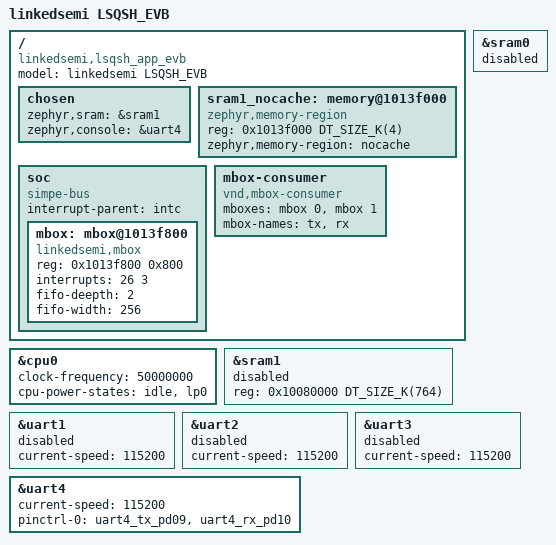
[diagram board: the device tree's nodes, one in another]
/*
 * Copyright (c) 2021, Teslabs Engineering S.L.
 * SPDX-License-Identifier: Apache-2.0
 */

// #include <gigadevice/gd32vf103Xb.dtsi>
// #include "gd32vf103v_eval-pinctrl.dtsi"
/dts-v1/;
#include <riscv/linkedsemi/lsqsh.dtsi>
#include "lsqsh_evb-pinctrl.dtsi"
#include <zephyr/dt-bindings/pinctrl/lsqsh-pinctrl.h>

#define BTN_GPIO_FLAGS (GPIO_ACTIVE_HIGH | GPIO_PULL_UP)

/ {
    model = "linkedsemi LSQSH_EVB";
    compatible = "linkedsemi,lsqsh_app_evb";

    chosen {
        zephyr,sram = &sram1;
        zephyr,console = &uart4;
    };

    sram1_nocache: memory@1013f000{
        compatible = "zephyr,memory-region", "mmio-sram";
        reg = <0x1013f000 DT_SIZE_K(4)>;
        device_type = "memory";
        zephyr,memory-region = "nocache";
    };

    soc {
        compatible = "simpe-bus";
        #address-cells = <1>;
        #size-cells = <1>;
        interrupt-parent = <&intc>;

        mbox: mbox@1013f800 {
            compatible = "linkedsemi,mbox";
            reg = <0x1013f800 0x800>;
            interrupts = <26 3>;
            fifo-deepth = <2>;
            fifo-width = <256>;
            #mbox-cells = <1>;
        };
    };

    mbox-consumer {
        compatible = "vnd,mbox-consumer";
        mboxes = <&mbox 0>, <&mbox 1>;
        mbox-names = "tx", "rx";
    };
};

&cpu0 {
    clock-frequency = <50000000>;
    cpu-power-states = <&idle &lp0>;
};

&sram0 {
    status = "disabled";
};

&sram1 {
    reg = <0x10080000 DT_SIZE_K(764)>;
    status = "disabled";
};

&uart1 {
    status = "disabled";
    current-speed = <115200>;
};

&uart2 {
    status = "disabled";
    current-speed = <115200>;
};

&uart3 {
    status = "disabled";
    current-speed = <115200>;
};

&uart4 {
    status = "okay";
    current-speed = <115200>;
    pinctrl-0 = <&uart4_tx_pd09 &uart4_rx_pd10>;
    pinctrl-names = "default";
};
